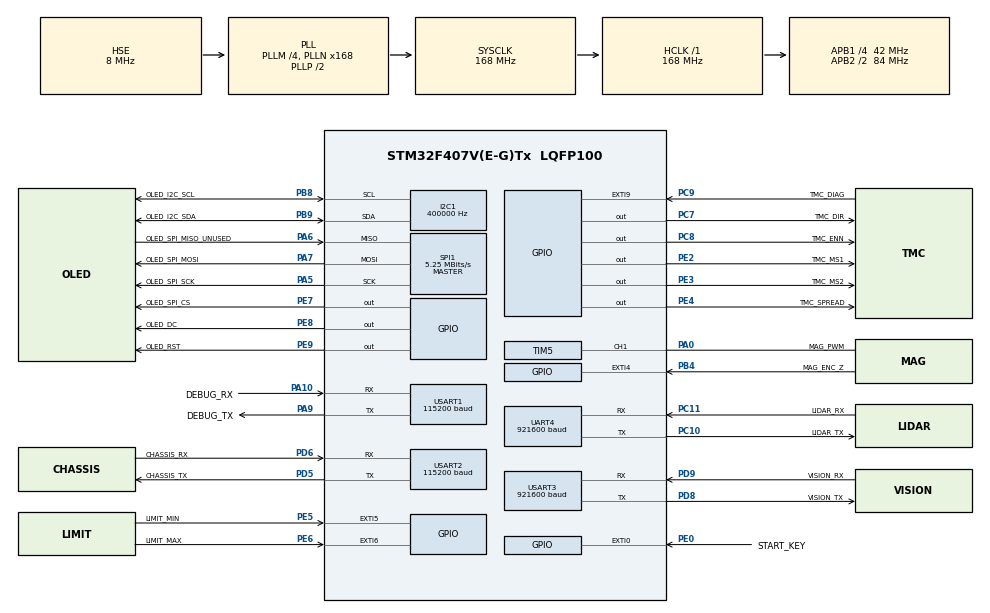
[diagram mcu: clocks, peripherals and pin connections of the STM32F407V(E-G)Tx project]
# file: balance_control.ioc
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ADC1.Channel-10\#ChannelRegularConversion=ADC_CHANNEL_10
ADC1.ContinuousConvMode=DISABLE
ADC1.DMAContinuousRequests=ENABLE
ADC1.ExternalTrigConv=ADC_EXTERNALTRIGCONV_T3_TRGO
ADC1.ExternalTrigConvEdge=ADC_EXTERNALTRIGCONVEDGE_RISING
ADC1.NbrOfConversion=1
ADC1.Resolution=ADC_RESOLUTION_12B
ADC1.SamplingTime-10\#ChannelRegularConversion=ADC_SAMPLETIME_15CYCLES
Dma.ADC1.0.Direction=DMA_PERIPH_TO_MEMORY
Dma.ADC1.0.FIFOMode=DMA_FIFOMODE_DISABLE
Dma.ADC1.0.Instance=DMA2_Stream0
Dma.ADC1.0.MemDataAlignment=DMA_MDATAALIGN_HALFWORD
Dma.ADC1.0.MemInc=DMA_MINC_ENABLE
Dma.ADC1.0.Mode=DMA_CIRCULAR
Dma.ADC1.0.PeriphDataAlignment=DMA_PDATAALIGN_HALFWORD
Dma.ADC1.0.PeriphInc=DMA_PINC_DISABLE
Dma.ADC1.0.Priority=DMA_PRIORITY_HIGH
Dma.Request0=ADC1
Dma.Request1=SPI1_TX
Dma.Request2=USART1_RX
Dma.Request3=USART1_TX
Dma.Request4=USART2_RX
Dma.Request5=USART2_TX
Dma.Request6=USART3_RX
Dma.Request7=USART3_TX
Dma.Request8=UART4_RX
Dma.Request9=UART4_TX
Dma.SPI1_TX.1.Direction=DMA_MEMORY_TO_PERIPH
Dma.SPI1_TX.1.FIFOMode=DMA_FIFOMODE_DISABLE
Dma.SPI1_TX.1.Instance=DMA2_Stream3
Dma.SPI1_TX.1.MemDataAlignment=DMA_MDATAALIGN_BYTE
Dma.SPI1_TX.1.MemInc=DMA_MINC_ENABLE
Dma.SPI1_TX.1.Mode=DMA_NORMAL
Dma.SPI1_TX.1.PeriphDataAlignment=DMA_PDATAALIGN_BYTE
Dma.SPI1_TX.1.PeriphInc=DMA_PINC_DISABLE
Dma.SPI1_TX.1.Priority=DMA_PRIORITY_LOW
Dma.UART4_RX.8.Direction=DMA_PERIPH_TO_MEMORY
Dma.UART4_RX.8.FIFOMode=DMA_FIFOMODE_DISABLE
Dma.UART4_RX.8.Instance=DMA1_Stream2
Dma.UART4_RX.8.MemDataAlignment=DMA_MDATAALIGN_BYTE
Dma.UART4_RX.8.MemInc=DMA_MINC_ENABLE
Dma.UART4_RX.8.Mode=DMA_CIRCULAR
Dma.UART4_RX.8.PeriphDataAlignment=DMA_PDATAALIGN_BYTE
Dma.UART4_RX.8.PeriphInc=DMA_PINC_DISABLE
Dma.UART4_RX.8.Priority=DMA_PRIORITY_HIGH
Dma.UART4_TX.9.Direction=DMA_MEMORY_TO_PERIPH
Dma.UART4_TX.9.FIFOMode=DMA_FIFOMODE_DISABLE
Dma.UART4_TX.9.Instance=DMA1_Stream4
Dma.UART4_TX.9.MemDataAlignment=DMA_MDATAALIGN_BYTE
Dma.UART4_TX.9.MemInc=DMA_MINC_ENABLE
Dma.UART4_TX.9.Mode=DMA_NORMAL
Dma.UART4_TX.9.PeriphDataAlignment=DMA_PDATAALIGN_BYTE
Dma.UART4_TX.9.PeriphInc=DMA_PINC_DISABLE
Dma.UART4_TX.9.Priority=DMA_PRIORITY_MEDIUM
Dma.USART1_RX.2.Direction=DMA_PERIPH_TO_MEMORY
Dma.USART1_RX.2.FIFOMode=DMA_FIFOMODE_DISABLE
Dma.USART1_RX.2.Instance=DMA2_Stream2
Dma.USART1_RX.2.MemDataAlignment=DMA_MDATAALIGN_BYTE
Dma.USART1_RX.2.MemInc=DMA_MINC_ENABLE
Dma.USART1_RX.2.Mode=DMA_CIRCULAR
Dma.USART1_RX.2.PeriphDataAlignment=DMA_PDATAALIGN_BYTE
Dma.USART1_RX.2.PeriphInc=DMA_PINC_DISABLE
Dma.USART1_RX.2.Priority=DMA_PRIORITY_LOW
Dma.USART1_TX.3.Direction=DMA_MEMORY_TO_PERIPH
Dma.USART1_TX.3.FIFOMode=DMA_FIFOMODE_DISABLE
Dma.USART1_TX.3.Instance=DMA2_Stream7
Dma.USART1_TX.3.MemDataAlignment=DMA_MDATAALIGN_BYTE
Dma.USART1_TX.3.MemInc=DMA_MINC_ENABLE
Dma.USART1_TX.3.Mode=DMA_NORMAL
Dma.USART1_TX.3.PeriphDataAlignment=DMA_PDATAALIGN_BYTE
Dma.USART1_TX.3.PeriphInc=DMA_PINC_DISABLE
Dma.USART1_TX.3.Priority=DMA_PRIORITY_LOW
Dma.USART2_RX.4.Direction=DMA_PERIPH_TO_MEMORY
Dma.USART2_RX.4.FIFOMode=DMA_FIFOMODE_DISABLE
Dma.USART2_RX.4.Instance=DMA1_Stream5
Dma.USART2_RX.4.MemDataAlignment=DMA_MDATAALIGN_BYTE
Dma.USART2_RX.4.MemInc=DMA_MINC_ENABLE
Dma.USART2_RX.4.Mode=DMA_CIRCULAR
Dma.USART2_RX.4.PeriphDataAlignment=DMA_PDATAALIGN_BYTE
Dma.USART2_RX.4.PeriphInc=DMA_PINC_DISABLE
Dma.USART2_RX.4.Priority=DMA_PRIORITY_HIGH
Dma.USART2_TX.5.Direction=DMA_MEMORY_TO_PERIPH
Dma.USART2_TX.5.FIFOMode=DMA_FIFOMODE_DISABLE
Dma.USART2_TX.5.Instance=DMA1_Stream6
Dma.USART2_TX.5.MemDataAlignment=DMA_MDATAALIGN_BYTE
Dma.USART2_TX.5.MemInc=DMA_MINC_ENABLE
Dma.USART2_TX.5.Mode=DMA_NORMAL
Dma.USART2_TX.5.PeriphDataAlignment=DMA_PDATAALIGN_BYTE
Dma.USART2_TX.5.PeriphInc=DMA_PINC_DISABLE
Dma.USART2_TX.5.Priority=DMA_PRIORITY_MEDIUM
Dma.USART3_RX.6.Direction=DMA_PERIPH_TO_MEMORY
Dma.USART3_RX.6.FIFOMode=DMA_FIFOMODE_DISABLE
Dma.USART3_RX.6.Instance=DMA1_Stream1
Dma.USART3_RX.6.MemDataAlignment=DMA_MDATAALIGN_BYTE
Dma.USART3_RX.6.MemInc=DMA_MINC_ENABLE
Dma.USART3_RX.6.Mode=DMA_CIRCULAR
Dma.USART3_RX.6.PeriphDataAlignment=DMA_PDATAALIGN_BYTE
Dma.USART3_RX.6.PeriphInc=DMA_PINC_DISABLE
Dma.USART3_RX.6.Priority=DMA_PRIORITY_HIGH
Dma.USART3_TX.7.Direction=DMA_MEMORY_TO_PERIPH
Dma.USART3_TX.7.FIFOMode=DMA_FIFOMODE_DISABLE
Dma.USART3_TX.7.Instance=DMA1_Stream3
Dma.USART3_TX.7.MemDataAlignment=DMA_MDATAALIGN_BYTE
Dma.USART3_TX.7.MemInc=DMA_MINC_ENABLE
Dma.USART3_TX.7.Mode=DMA_NORMAL
Dma.USART3_TX.7.PeriphDataAlignment=DMA_PDATAALIGN_BYTE
Dma.USART3_TX.7.PeriphInc=DMA_PINC_DISABLE
Dma.USART3_TX.7.Priority=DMA_PRIORITY_MEDIUM
I2C1.ClockSpeed=400000
Mcu.Family=STM32F4
Mcu.Name=STM32F407V(E-G)Tx
Mcu.Package=LQFP100
NVIC.DMA1_Stream1_IRQn=true\:5\:0\:false\:false\:true\:true\:true\:true
NVIC.DMA1_Stream2_IRQn=true\:5\:0\:false\:false\:true\:true\:true\:true
NVIC.DMA1_Stream3_IRQn=true\:5\:0\:false\:false\:true\:true\:true\:true
NVIC.DMA1_Stream4_IRQn=true\:5\:0\:false\:false\:true\:true\:true\:true
NVIC.DMA1_Stream5_IRQn=true\:5\:0\:false\:false\:true\:true\:true\:true
NVIC.DMA1_Stream6_IRQn=true\:5\:0\:false\:false\:true\:true\:true\:true
NVIC.DMA2_Stream0_IRQn=true\:2\:0\:false\:false\:true\:true\:true\:true
NVIC.DMA2_Stream2_IRQn=true\:5\:0\:false\:false\:true\:true\:true\:true
NVIC.DMA2_Stream3_IRQn=true\:6\:0\:false\:false\:true\:true\:true\:true
NVIC.DMA2_Stream7_IRQn=true\:6\:0\:false\:false\:true\:true\:true\:true
NVIC.PriorityGroup=NVIC_PRIORITYGROUP_4
NVIC.SPI1_IRQn=true\:6\:0\:false\:false\:true\:true\:true\:true
NVIC.TIM5_IRQn=true\:3\:0\:false\:false\:true\:true\:true\:true
NVIC.TIM6_DAC_IRQn=true\:1\:0\:false\:false\:true\:true\:true\:true
NVIC.TIM8_UP_TIM13_IRQn=true\:2\:0\:false\:false\:true\:true\:true\:true
NVIC.UART4_IRQn=true\:5\:0\:false\:false\:true\:true\:true\:true
NVIC.USART1_IRQn=true\:6\:0\:false\:false\:true\:true\:true\:true
NVIC.USART2_IRQn=true\:5\:0\:false\:false\:true\:true\:true\:true
NVIC.USART3_IRQn=true\:5\:0\:false\:false\:true\:true\:true\:true
PA0-WKUP.GPIO_Label=MAG_PWM
PA0-WKUP.Signal=S_TIM5_CH1
PA10.GPIO_Label=DEBUG_RX
PA10.Mode=Asynchronous
PA10.Signal=USART1_RX
PA13.Mode=Serial_Wire
PA13.Signal=SYS_JTMS-SWDIO
PA14.Mode=Serial_Wire
PA14.Signal=SYS_JTCK-SWCLK
PA15.GPIO_Label=MAG_ENC_A
PA15.Signal=S_TIM2_CH1_ETR
PA5.GPIO_Label=OLED_SPI_SCK
PA5.Mode=Full_Duplex_Master
PA5.Signal=SPI1_SCK
PA6.GPIO_Label=OLED_SPI_MISO_UNUSED
PA6.Mode=Full_Duplex_Master
PA6.Signal=SPI1_MISO
PA7.GPIO_Label=OLED_SPI_MOSI
PA7.Mode=Full_Duplex_Master
PA7.Signal=SPI1_MOSI
PA9.GPIO_Label=DEBUG_TX
PA9.Mode=Asynchronous
PA9.Signal=USART1_TX
PB3.GPIO_Label=MAG_ENC_B
PB3.Signal=S_TIM2_CH2
PB4.GPIO_Label=MAG_ENC_Z
PB4.GPIO_ModeDefaultEXTI=GPIO_MODE_IT_RISING
PB4.GPIO_PuPd=GPIO_PULLUP
PB4.Signal=GPXTI4
PB8.GPIO_Label=OLED_I2C_SCL
PB8.Mode=I2C
PB8.Signal=I2C1_SCL
PB9.GPIO_Label=OLED_I2C_SDA
PB9.Mode=I2C
PB9.Signal=I2C1_SDA
PC0.GPIO_Label=ANGLE_POT_ADC
PC0.Signal=ADCx_IN10
PC10.GPIO_Label=LIDAR_TX
PC10.Mode=Asynchronous
PC10.Signal=UART4_TX
PC11.GPIO_Label=LIDAR_RX
PC11.Mode=Asynchronous
PC11.Signal=UART4_RX
PC6.GPIO_Label=TMC_STEP
PC6.Signal=S_TIM8_CH1
PC7.GPIO_Label=TMC_DIR
PC7.GPIO_PuPd=GPIO_PULLDOWN
PC7.GPIO_Speed=GPIO_SPEED_FREQ_HIGH
PC7.PinState=GPIO_PIN_RESET
PC7.Signal=GPIO_Output
PC8.GPIO_Label=TMC_ENN
PC8.GPIO_PuPd=GPIO_PULLUP
PC8.GPIO_Speed=GPIO_SPEED_FREQ_HIGH
PC8.PinState=GPIO_PIN_SET
PC8.Signal=GPIO_Output
PC9.GPIO_Label=TMC_DIAG
PC9.GPIO_ModeDefaultEXTI=GPIO_MODE_IT_RISING
PC9.GPIO_PuPd=GPIO_PULLUP
PC9.Signal=GPXTI9
PD5.GPIO_Label=CHASSIS_TX
PD5.Mode=Asynchronous
PD5.Signal=USART2_TX
PD6.GPIO_Label=CHASSIS_RX
PD6.Mode=Asynchronous
PD6.Signal=USART2_RX
PD8.GPIO_Label=VISION_TX
PD8.Mode=Asynchronous
PD8.Signal=USART3_TX
PD9.GPIO_Label=VISION_RX
PD9.Mode=Asynchronous
PD9.Signal=USART3_RX
PE0.GPIO_Label=START_KEY
PE0.GPIO_ModeDefaultEXTI=GPIO_MODE_IT_FALLING
PE0.GPIO_PuPd=GPIO_PULLUP
PE0.Signal=GPXTI0
PE2.GPIO_Label=TMC_MS1
PE2.GPIO_PuPd=GPIO_PULLUP
PE2.PinState=GPIO_PIN_SET
PE2.Signal=GPIO_Output
PE3.GPIO_Label=TMC_MS2
PE3.GPIO_PuPd=GPIO_PULLUP
PE3.PinState=GPIO_PIN_SET
PE3.Signal=GPIO_Output
PE4.GPIO_Label=TMC_SPREAD
PE4.GPIO_PuPd=GPIO_PULLUP
PE4.PinState=GPIO_PIN_SET
PE4.Signal=GPIO_Output
PE5.GPIO_Label=LIMIT_MIN
PE5.GPIO_ModeDefaultEXTI=GPIO_MODE_IT_RISING_FALLING
PE5.GPIO_PuPd=GPIO_PULLUP
PE5.Signal=GPXTI5
PE6.GPIO_Label=LIMIT_MAX
PE6.GPIO_ModeDefaultEXTI=GPIO_MODE_IT_RISING_FALLING
PE6.GPIO_PuPd=GPIO_PULLUP
PE6.Signal=GPXTI6
PE7.GPIO_Label=OLED_SPI_CS
PE7.GPIO_PuPd=GPIO_PULLUP
PE7.PinState=GPIO_PIN_SET
PE7.Signal=GPIO_Output
PE8.GPIO_Label=OLED_DC
PE8.GPIO_PuPd=GPIO_NOPULL
PE8.PinState=GPIO_PIN_RESET
PE8.Signal=GPIO_Output
PE9.GPIO_Label=OLED_RST
PE9.GPIO_PuPd=GPIO_PULLUP
PE9.PinState=GPIO_PIN_SET
PE9.Signal=GPIO_Output
PH0-OSC_IN.Mode=HSE-External-Oscillator
PH0-OSC_IN.Signal=RCC_OSC_IN
PH1-OSC_OUT.Mode=HSE-External-Oscillator
PH1-OSC_OUT.Signal=RCC_OSC_OUT
ProjectManager.HeapSize=0x400
ProjectManager.StackSize=0x800
ProjectManager.TargetToolchain=MDK-ARM V5.32
RCC.48MHZClocksFreq_Value=48000000
RCC.AHBFreq_Value=168000000
RCC.APB1CLKDivider=RCC_HCLK_DIV4
RCC.APB1Freq_Value=42000000
RCC.APB1TimFreq_Value=84000000
RCC.APB2CLKDivider=RCC_HCLK_DIV2
RCC.APB2Freq_Value=84000000
RCC.APB2TimFreq_Value=168000000
RCC.CortexFreq_Value=168000000
RCC.HCLKFreq_Value=168000000
RCC.HSE_VALUE=8000000
RCC.HSI_VALUE=16000000
RCC.LSE_VALUE=32768
RCC.PLLM=4
RCC.PLLN=168
RCC.PLLQ=7
RCC.PLLSourceVirtual=RCC_PLLSOURCE_HSE
RCC.RCC_RTC_Clock_Source=RCC_RTCCLKSOURCE_LSI
RCC.RCC_RTC_Clock_SourceVirtual=RCC_RTCCLKSOURCE_LSI
RCC.SYSCLKFreq_VALUE=168000000
RCC.SYSCLKSource=RCC_SYSCLKSOURCE_PLLCLK
RCC.VCOOutputFreq_Value=336000000
SH.S_TIM5_CH1.0=TIM5_CH1,PWM Input1
SH.S_TIM5_CH2.0=TIM5_CH2,PWM Input2
SPI1.BaudRatePrescaler=SPI_BAUDRATEPRESCALER_16
SPI1.CalculateBaudRate=5.25 MBits/s
SPI1.Direction=SPI_DIRECTION_2LINES
SPI1.Mode=SPI_MODE_MASTER
SPI1.VirtualType=VM_MASTER
TIM3.AutoReloadPreload=TIM_AUTORELOAD_PRELOAD_ENABLE
TIM3.Period=500-1
TIM3.Prescaler=84-1
TIM3.TIM_MasterOutputTrigger=TIM_TRGO_UPDATE
TIM2.EncoderMode=TIM_ENCODERMODE_TI12
TIM2.IC1Filter=6
TIM2.IC2Filter=6
TIM2.Period=4294967295
TIM5.Channel-PWM\ Input1=TIM_CHANNEL_1
TIM5.Channel-PWM\ Input2=TIM_CHANNEL_2
TIM5.Period=4294967295
TIM5.Prescaler=84-1
TIM6.AutoReloadPreload=TIM_AUTORELOAD_PRELOAD_ENABLE
TIM6.Period=1000-1
TIM6.Prescaler=84-1
TIM8.AutoReloadPreload=TIM_AUTORELOAD_PRELOAD_ENABLE
TIM8.Channel-PWM\ Generation1\ CH1=TIM_CHANNEL_1
TIM8.Period=1000-1
TIM8.Prescaler=168-1
TIM8.Pulse-PWM\ Generation1\ CH1=2
UART4.BaudRate=921600
UART4.VirtualMode=Asynchronous
USART1.BaudRate=115200
USART1.VirtualMode=VM_ASYNC
USART2.BaudRate=115200
USART2.VirtualMode=VM_ASYNC
USART3.BaudRate=921600
USART3.VirtualMode=VM_ASYNC
VP_TIM3_VS_ClockSourceINT.Mode=Internal
VP_TIM6_VS_ClockSourceINT.Mode=Enable_Timer
VP_TIM8_VS_ClockSourceINT.Mode=Internal
board=custom

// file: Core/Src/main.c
/* USER CODE BEGIN Header */
/**
  ******************************************************************************
  * @file           : main.c
  * @brief          : Main program body
  ******************************************************************************
  * @attention
  *
  * Copyright (c) 2026 STMicroelectronics.
  * All rights reserved.
  *
  * This software is licensed under terms that can be found in the LICENSE file
  * in the root directory of this software component.
  * If no LICENSE file comes with this software, it is provided AS-IS.
  *
  ******************************************************************************
  */
/* USER CODE END Header */
#include "main.h"
#include "adc.h"
#include "dma.h"
#include "i2c.h"
#include "spi.h"
#include "tim.h"
#include "usart.h"
#include "gpio.h"

/* USER CODE BEGIN Includes */
#include "user_runtime.h"

/* USER CODE END Includes */

void SystemClock_Config(void);

int main(void)
{

  /* MCU Configuration--------------------------------------------------------*/

  /* Reset of all peripherals, Initializes the Flash interface and the Systick. */
  HAL_Init();

  /* Configure the system clock */
  SystemClock_Config();

  /* Initialize all configured peripherals */
  MX_GPIO_Init();
  MX_DMA_Init();
  MX_ADC1_Init();
  MX_I2C1_Init();
  MX_SPI1_Init();
  MX_TIM2_Init();
  MX_TIM3_Init();
  MX_TIM5_Init();
  MX_TIM6_Init();
  MX_TIM8_Init();
  MX_UART4_Init();
  MX_USART1_UART_Init();
  MX_USART2_UART_Init();
  MX_USART3_UART_Init();
  /* USER CODE BEGIN 2 */
  User_Runtime_Init();

  /* USER CODE END 2 */

  /* Infinite loop */
  while (1)
  {

    /* USER CODE BEGIN 3 */
    User_Runtime_Run();
  }
  /* USER CODE END 3 */
}

void SystemClock_Config(void)
{
  RCC_OscInitTypeDef RCC_OscInitStruct = {0};
  RCC_ClkInitTypeDef RCC_ClkInitStruct = {0};

  /** Configure the main internal regulator output voltage
  */
  __HAL_RCC_PWR_CLK_ENABLE();
  __HAL_PWR_VOLTAGESCALING_CONFIG(PWR_REGULATOR_VOLTAGE_SCALE1);

  /** Initializes the RCC Oscillators according to the specified parameters
  * in the RCC_OscInitTypeDef structure.
  */
  RCC_OscInitStruct.OscillatorType = RCC_OSCILLATORTYPE_HSE;
  RCC_OscInitStruct.HSEState = RCC_HSE_ON;
  RCC_OscInitStruct.PLL.PLLState = RCC_PLL_ON;
  RCC_OscInitStruct.PLL.PLLSource = RCC_PLLSOURCE_HSE;
  RCC_OscInitStruct.PLL.PLLM = 4;
  RCC_OscInitStruct.PLL.PLLN = 168;
  RCC_OscInitStruct.PLL.PLLP = RCC_PLLP_DIV2;
  RCC_OscInitStruct.PLL.PLLQ = 7;
  if (HAL_RCC_OscConfig(&RCC_OscInitStruct) != HAL_OK)
  {
    Error_Handler();
  }

  /** Initializes the CPU, AHB and APB buses clocks
  */
  RCC_ClkInitStruct.ClockType = RCC_CLOCKTYPE_HCLK|RCC_CLOCKTYPE_SYSCLK
                              |RCC_CLOCKTYPE_PCLK1|RCC_CLOCKTYPE_PCLK2;
  RCC_ClkInitStruct.SYSCLKSource = RCC_SYSCLKSOURCE_PLLCLK;
  RCC_ClkInitStruct.AHBCLKDivider = RCC_SYSCLK_DIV1;
  RCC_ClkInitStruct.APB1CLKDivider = RCC_HCLK_DIV4;
  RCC_ClkInitStruct.APB2CLKDivider = RCC_HCLK_DIV2;

  if (HAL_RCC_ClockConfig(&RCC_ClkInitStruct, FLASH_LATENCY_5) != HAL_OK)
  {
    Error_Handler();
  }
}

void Error_Handler(void)
{
  __disable_irq();
  while (1)
  {
  }
}
